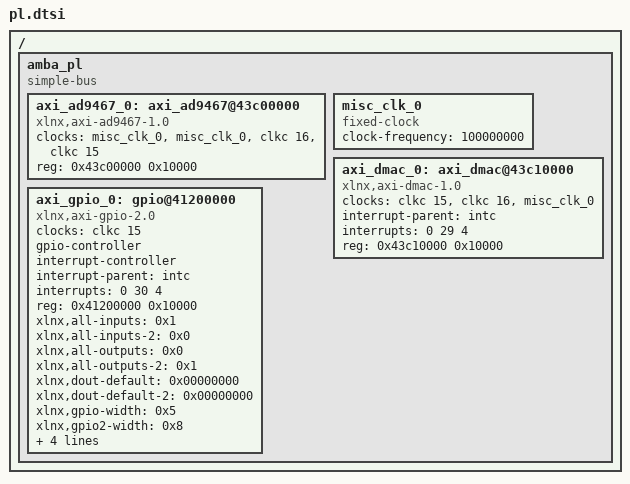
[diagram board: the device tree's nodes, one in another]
/*
 * CAUTION: This file is automatically generated by Xilinx.
 * Version: XSCT 2023.1
 * Today is: Sun May 26 17:13:32 2024
 */


/ {
	amba_pl: amba_pl {
		#address-cells = <1>;
		#size-cells = <1>;
		compatible = "simple-bus";
		ranges ;
		axi_ad9467_0: axi_ad9467@43c00000 {
			/* This is a place holder node for a custom IP, user may need to update the entries */
			clock-names = "adc_clk_in_p", "adc_clk_in_n", "delay_clk", "s_axi_aclk";
			clocks = <&misc_clk_0>, <&misc_clk_0>, <&clkc 16>, <&clkc 15>;
			compatible = "xlnx,axi-ad9467-1.0";
			reg = <0x43c00000 0x10000>;
		};
		misc_clk_0: misc_clk_0 {
			#clock-cells = <0>;
			clock-frequency = <100000000>;
			compatible = "fixed-clock";
		};
		axi_dmac_0: axi_dmac@43c10000 {
			/* This is a place holder node for a custom IP, user may need to update the entries */
			clock-names = "s_axi_aclk", "m_dest_axi_aclk", "fifo_wr_clk";
			clocks = <&clkc 15>, <&clkc 16>, <&misc_clk_0>;
			compatible = "xlnx,axi-dmac-1.0";
			interrupt-names = "irq";
			interrupt-parent = <&intc>;
			interrupts = <0 29 4>;
			reg = <0x43c10000 0x10000>;
		};
		axi_gpio_0: gpio@41200000 {
			#gpio-cells = <2>;
			#interrupt-cells = <2>;
			clock-names = "s_axi_aclk";
			clocks = <&clkc 15>;
			compatible = "xlnx,axi-gpio-2.0", "xlnx,xps-gpio-1.00.a";
			gpio-controller ;
			interrupt-controller ;
			interrupt-names = "ip2intc_irpt";
			interrupt-parent = <&intc>;
			interrupts = <0 30 4>;
			reg = <0x41200000 0x10000>;
			xlnx,all-inputs = <0x1>;
			xlnx,all-inputs-2 = <0x0>;
			xlnx,all-outputs = <0x0>;
			xlnx,all-outputs-2 = <0x1>;
			xlnx,dout-default = <0x00000000>;
			xlnx,dout-default-2 = <0x00000000>;
			xlnx,gpio-width = <0x5>;
			xlnx,gpio2-width = <0x8>;
			xlnx,interrupt-present = <0x1>;
			xlnx,is-dual = <0x1>;
			xlnx,tri-default = <0xFFFFFFFF>;
			xlnx,tri-default-2 = <0xFFFFFFFF>;
		};
	};
};
